# AE1C1F4051920PH0_CM55_HE_View register map
Vendor: Alif Semiconductor; Series: E1; File version: 1.0
CPU: CM55 r1p0, selectable endian, MPU, FPU, double-precision FPU, DSP, VTOR, 8 interrupt priority bits, 1 SAU regions
Registers are 32-bit, read-write, reset 0x0 unless marked. A register's access mark holds for its fields unless they carry their own. Offsets are from the block's base; [hi:lo] are bit positions; {n}, {i} and the like mark numbered series; 'fields as' and 'values as' point back to an identical list.

## CLKCTL_PER_SLV
Base 0x4902F000
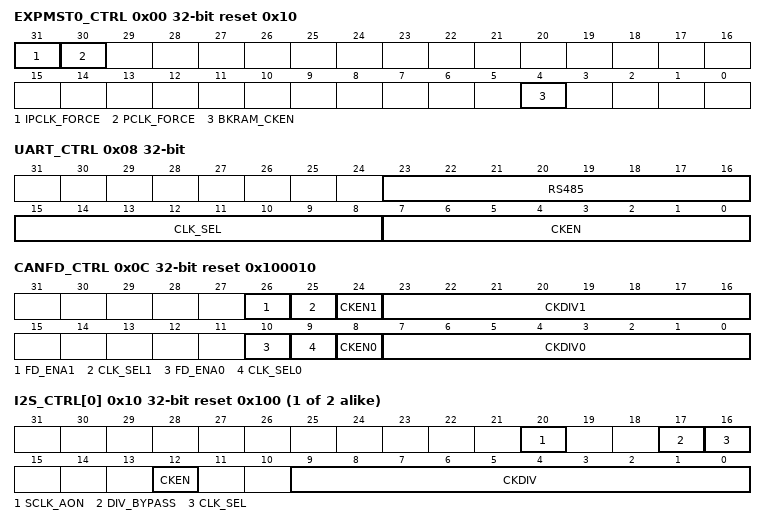
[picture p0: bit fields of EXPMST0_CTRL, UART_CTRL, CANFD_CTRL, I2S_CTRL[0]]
0x00 EXPMST0_CTRL reset 0x10 — Clock Control Register
  [31] IPCLK_FORCE
    0=Clock force disabled; 1=Force peripherals functional clocks on, bypass clock gating
  [30] PCLK_FORCE
    0=Clock force disabled; 1=Force APB interface clocks (PCLKs) on, bypass clock gating
  [4] BKRAM_CKEN — Clock enable for Utility SRAM
    0=Disable clock; 1=Enable clock
0x08 UART_CTRL — UART Control Register
  [23:16] RS485 ro — UART[5-4] RS485 Status. One bit for each module. Bits[23-22] are reserved, bit 21 --> UART5, bit 20 --> UART4. Bits[19-16] are reserved.
    0=UART not in RS485 mode; 1=UART is in RS485 mode
  [15:8] CLK_SEL — UART[5-0]_SCLK Select. One bit for each module. Bits[15-14] are reserved, Bit 13 --> UART5, bit 8 --> UART0.
    0=38.4 MHz; 1=SYST_PCLK clock
  [7:0] CKEN — UART[5-0] Enable. One bit for each module. Bits[7-6] are reserved, bit 5 --> UART5, bit 0 --> UART0
    0=Disable UART[5-0] module; 1=Enable UART[5-0] module
0x0C CANFD_CTRL reset 0x100010 — CANFD Control Register
  [26] FD_ENA1 — CANFD1 FD-mode enable
    0=Disable FD-mode; 1=Enable FD-mode
  [25] CLK_SEL1 — CANFD1 functional clock source select
    0=Select 38.4 MHz oscillator clock (HFOSC_CLK); 1=Select 160 MHz PLL clock (PERIPH_CLK)
  [24] CKEN1 — CANFD1 clocks enable
    0=Disable; 1=Enable
  [23:16] CKDIV1 — CANFD1 functional clock divisor n: Clock divided by n
    0=Illegal values; 1=Illegal values; 2=Clock divided by 2; 3=Clock divided by 3
  [10] FD_ENA0 — CANFD0 FD-mode enable
    0=Disable FD-mode; 1=Enable FD-mode
  [9] CLK_SEL0 — CANFD0 functional clock source select
    values as CLK_SEL1
  [8] CKEN0 — CANFD0 clocks enable
    0=Disable; 1=Enable
  [7:0] CKDIV0 — CANFD0 functional clock divisor n: Clock divided by n
    values as CKDIV1
{0x10+4i} I2S_CTRL[{i}] (i=0..1) reset 0x100 — I2Sn Control Register
  [20] SCLK_AON — I2S clock output to external device always on
    0=I2S clock output (I2S_SCLK) in gated mode; 1=I2S clock output (I2S_SCLK) in always on mode
  [17] DIV_BYPASS — I2S clock divider bypass
    0=Do not bypass clock divider; 1=Bypass clock divider
  [16] CLK_SEL — I2S functional clock source select
    0=Select 76.8 MHz crystal-oscillator clock (76M8_CLK); 1=Select audio PLL clock (AUDIO_PLL_CLK)
  [12] CKEN — I2S clocks enable
    0=Disable clocks; 1=Enable clocks
  [9:0] CKDIV — I2S functional clock divisor n: Clock divided by n
    values as CANFD_CTRL.CKDIV1
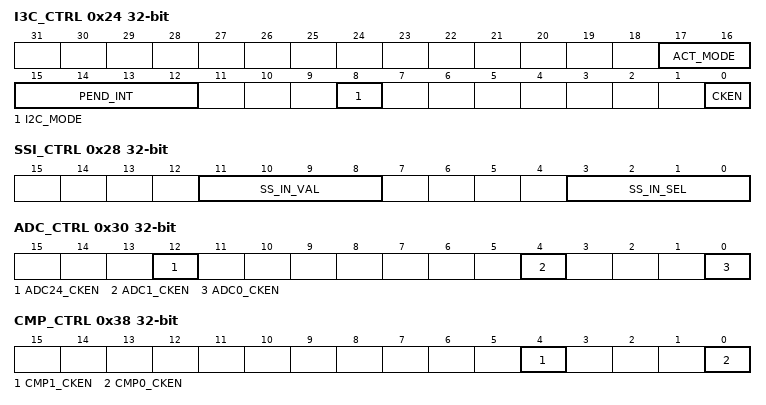
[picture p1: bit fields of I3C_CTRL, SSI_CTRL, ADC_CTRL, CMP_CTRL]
0x24 I3C_CTRL — I3C Control Register
  [17:16] ACT_MODE — I3C slave activity mode for GETSTATUS CCC
  [15:12] PEND_INT — I3C pending interrupt information for GETSTATUS CCC
  [8] I2C_MODE — I2C or I3C mode select
  [0] CKEN — I3C clocks enable
    0=Disable clock; 1=Enable clock
0x28 SSI_CTRL — SPI Control Register
  [11:8] SS_IN_VAL — SS_IN Value One bit for each SPI module: - Bit 11: Reserved - Bit 10: SPI2 - Bit 8: SPI0 When SS_IN_SEL = 0x1, the programmed SS_IN_VAL is fed to SPI module. Note: If the corresponding SPI module is configured as a master, the associated bit in this field should be set to 0x1.
  [3:0] SS_IN_SEL — SS_IN Mode Select One bit for each SPI module: - Bit 3: Reserved - Bit 2: SPI2 - Bit 0: SPI0 Note: If the corresponding SPI module is configured as a master, the associated bit in this field should be set to 0x1. If the corresponding SPI module is configured as a slave, and the master device is driving a slave select signal, the associated bit in this field should be set to 0x0. If the master device is not driving a slave select signal, the associated bit in this field should be set to 0x1, and the associated bit in SS_IN_VAL field should be set to 0x0.
    0=SS_IN from I/O pin; 1=SS_IN from SS_IN_VAL
0x30 ADC_CTRL — ADC Control Register
  [12] ADC24_CKEN — ADC24 clock enable
    0=Disable ADC24 clock; 1=Enable ADC24 clock
  [4] ADC1_CKEN — ADC121 clock enable
    0=Disable ADC121 clock; 1=Enable ADC121 clock
  [0] ADC0_CKEN — ADC120 clock enable
    0=Disable ADC120 clock; 1=Enable ADC120 clock
0x34 DAC_CTRL — DAC Control Register
  [0] DAC0_CKEN — DAC12 clock enable
    0=Disable DAC12 clock; 1=Enable DAC12 clock
0x38 CMP_CTRL — CMP Control Register
  [4] CMP1_CKEN — CMP1 clock enable
    0=Disable CMP1 clock; 1=Enable CMP1 clock
  [0] CMP0_CKEN — CMP0 clock enable
    0=Disable CMP0 clock; 1=Enable CMP0 clock
0x3C OSPI_CTRL — OSPI Control Register
  [0] CKEN — OSPI clock enable
    0=Disable clock; 1=Enable clock
0x40 FREQ_MON_CTRL0 — Frequency Monitor 0 Control Register
  [31:0] CTRL — Input count value of the HFXO clock to be measured or calibrated.
0x44 FREQ_MON_STAT0 ro — Frequency Monitor 0 Status Register
  [31:0] STAT — Output count value of the 160 MHz PLL calibrating clock.
0x48 FREQ_MON_CTRL1 — Frequency Monitor 1 Control Register
  [31:0] CTRL — Input count value of the 160 MHz clock to be measured or calibrated.
0x4C FREQ_MON_STAT1 ro — Frequency Monitor 1 Status Register
  fields as FREQ_MON_STAT0
0x50 I2C0_CTRL — I2C0 Control Register
  [0] CKEN — I2C0 clock enable
    0=Disable clock; 1=Enable clock
0x54 I2C1_CTRL — I2C1 Control Register
  [0] CKEN — I2C1 clock enable
    0=Disable clock; 1=Enable clock
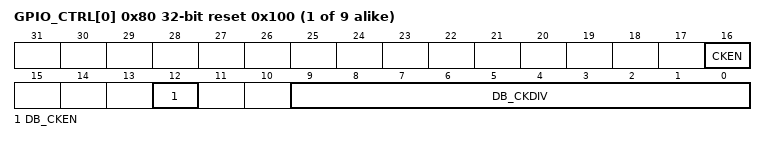
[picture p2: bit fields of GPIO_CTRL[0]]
{0x80+4i} GPIO_CTRL[{i}] (i=0..8) reset 0x100 — GPIOn Control Register
  [16] CKEN — GPIOn clock control
    0=GPIOn clock is enabled for two clock cycles when accessed by the host processor; 1=GPIOn clock is always active (enabled indefinitely)
  [12] DB_CKEN — Enable GPIOn debounce clock
    0=Disable clock; 1=Enable clock
  [9:0] DB_CKDIV — GPIOn debounce clock divisor All other values: Clock divided by 1024
    1=Clock divided by 2; 2=Clock divided by 4; 4=Clock divided by 8; 8=Clock divided by 16; 16=Clock divided by 32; 32=Clock divided by 64; 64=Clock divided by 128; 128=Clock divided by 256; 0x100=Clock divided by 512; 0x200=Clock divided by 1024
